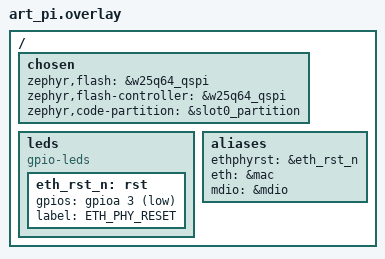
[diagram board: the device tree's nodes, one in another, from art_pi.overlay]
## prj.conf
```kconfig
# # 与 A 相同的网络 / zperf / shell 基础：
# CONFIG_NETWORKING=y
# CONFIG_NET_L2_ETHERNET=y
# CONFIG_NET_IPV4=y

# CONFIG_NET_SOCKETS=y
# CONFIG_NET_UDP=y            # 你已开；确认仍为 y
# CONFIG_NET_TCP=y            # 继续保持关闭，省 ROM

# CONFIG_NET_DHCPV4=y
# CONFIG_NET_IPV6=y
# CONFIG_DNS_RESOLVER=y

# CONFIG_NET_ZPERF=y
# CONFIG_ZPERF_SESSION_PER_THREAD=n            # 关多会话节省体积 :contentReference[oaicite:6]{index=6}

# CONFIG_NET_SHELL=y                           # 只要 ping / iface 等基础命令即可 :contentReference[oaicite:7]{index=7}

# CONFIG_SHELL=y
# CONFIG_SHELL_BACKEND_SERIAL=y
# CONFIG_SHELL_MINIMAL=y                       # 极简 Shell :contentReference[oaicite:8]{index=8}
# CONFIG_SHELL_CMDS=y
# CONFIG_SHELL_TAB=y
# CONFIG_SHELL_TAB_AUTOCOMPLETION=y           # 需要自动补全就开；非常在意体积可关 :contentReference[oaicite:9]{index=9}
# CONFIG_SHELL_HELP=y
# CONFIG_SHELL_HISTORY=y

# # 完全关闭日志（最省 Flash；失去时间戳）
# CONFIG_LOG=n

# CONFIG_ETH_STM32_HAL=y

# # 只扩 TX，不动 RX（下载方向现在速度已经很高）  增加作用不大
# # CONFIG_NET_PKT_TX_COUNT=48
# # CONFIG_NET_BUF_TX_COUNT=192


# # 可选：把单个 net_buf 的数据块扩大，减少一次发送的分片数量
# #（会多占 RAM；若 RAM 够，设 512 是折中；默认通常较小）   此处增加有效果，只能增加一点网速
# CONFIG_NET_BUF_DATA_SIZE=512
# #开启硬件校验和 offload（降低 CPU 负担）
# CONFIG_ETH_STM32_HW_CHECKSUM=y
# #RX 线程保持抢占（接收方向更及时；默认已是 y）
# CONFIG_ETH_STM32_HAL_RX_THREAD_PREEMPTIVE=y



# 与 A 相同的网络 / zperf / shell 基础：
CONFIG_NETWORKING=y
CONFIG_NET_L2_ETHERNET=y
CONFIG_NET_IPV4=y

CONFIG_NET_SOCKETS=y
CONFIG_NET_UDP=y            # 你已开；确认仍为 y
CONFIG_NET_TCP=n            # 继续保持关闭，省 ROM

CONFIG_NET_DHCPV4=y
CONFIG_NET_IPV6=n
CONFIG_DNS_RESOLVER=n

CONFIG_NET_ZPERF=y
CONFIG_ZPERF_SESSION_PER_THREAD=n            # 关多会话节省体积 :contentReference[oaicite:6]{index=6}

CONFIG_NET_SHELL=y                           # 只要 ping / iface 等基础命令即可 :contentReference[oaicite:7]{index=7}

CONFIG_SHELL=y
CONFIG_SHELL_BACKEND_SERIAL=y
CONFIG_SHELL_MINIMAL=y                       # 极简 Shell :contentReference[oaicite:8]{index=8}
CONFIG_SHELL_CMDS=n
CONFIG_SHELL_TAB=n
CONFIG_SHELL_TAB_AUTOCOMPLETION=n            # 需要自动补全就开；非常在意体积可关 :contentReference[oaicite:9]{index=9}
CONFIG_SHELL_HELP=n
CONFIG_SHELL_HISTORY=n

# 完全关闭日志（最省 Flash；失去时间戳）
CONFIG_LOG=n

CONFIG_ETH_STM32_HAL=y

# 只扩 TX，不动 RX（下载方向现在速度已经很高）  增加作用不大
# CONFIG_NET_PKT_TX_COUNT=48
# CONFIG_NET_BUF_TX_COUNT=192


# 可选：把单个 net_buf 的数据块扩大，减少一次发送的分片数量
#（会多占 RAM；若 RAM 够，设 512 是折中；默认通常较小）   此处增加有效果，只能增加一点网速
CONFIG_NET_BUF_DATA_SIZE=512
#开启硬件校验和 offload（降低 CPU 负担）
CONFIG_ETH_STM32_HW_CHECKSUM=y
#RX 线程保持抢占（接收方向更及时；默认已是 y）
#CONFIG_ETH_STM32_HAL_RX_THREAD_PREEMPTIVE=y

CONFIG_PICOLIBC_USE_MODULE=y

#For UDP
CONFIG_NET_ZPERF_MAX_PACKET_SIZE=1470
```

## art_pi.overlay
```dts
/*
 * Copyright (c) 2025 STMicroelectronics
 *
 * SPDX-License-Identifier: Apache-2.0
 */

/*
 * Define the device, controller and partition to be the external memory
 * for running the application in external NOR from MCUboot
 */
/ {
	chosen {
		zephyr,flash = &w25q64_qspi;
		zephyr,flash-controller = &w25q64_qspi;
		zephyr,code-partition = &slot0_partition;
	};
};

/ {
    leds {
        compatible = "gpio-leds";
        status = "okay";

        eth_rst_n: rst {
            gpios = <&gpioa 3 GPIO_ACTIVE_LOW>; 
            label = "ETH_PHY_RESET";
         };
    };

    aliases {
		ethphyrst = &eth_rst_n;   
		eth = &mac;
		mdio = &mdio;
	};
};
```

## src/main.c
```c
/*
 * SPDX-License-Identifier: Apache-2.0
 *
 * STM32 + LAN8720A (RMII) 以太网连网（DHCP）
 * - 使用 Zephyr logging（自带时间戳）
 * - 接口 UP 后立即 net_dhcpv4_restart()（跳过初始随机等待）
 * - 监听链路与 IPv4 地址事件；断线->stop，重连->restart，并在拿到地址时打印
 */

#include <zephyr/kernel.h>
#include <zephyr/device.h>
#include <zephyr/drivers/gpio.h>
#include <zephyr/net/net_if.h>
#include <zephyr/net/net_ip.h>
#include <zephyr/net/net_core.h>
#include <zephyr/net/net_mgmt.h>
#include <zephyr/net/dhcpv4.h>
#include <zephyr/net/ethernet_mgmt.h>
#include <zephyr/logging/log.h>
#include <string.h>
#include <stm32h7xx_hal_eth.h>   // 提供 ETH_TX_DESC_CNT / ETH_RX_DESC_CNT

// LOG_MODULE_REGISTER(app, LOG_LEVEL_INF);

#if !IS_ENABLED(CONFIG_LOG)
  #define LOG_INF(fmt, ...) printk(fmt "\n", ##__VA_ARGS__)
  #define LOG_WRN(fmt, ...) printk("[WRN] " fmt "\n", ##__VA_ARGS__)
  #define LOG_ERR(fmt, ...) printk("[ERR] " fmt "\n", ##__VA_ARGS__)
  #define LOG_MODULE_REGISTER(a, b)
#endif


/* 兼容：若未定义以太网 CARRIER 事件，则退回用 IF_UP/IF_DOWN */
#ifndef NET_EVENT_ETHERNET_CARRIER_ON
#define NET_EVENT_ETHERNET_CARRIER_ON  NET_EVENT_IF_UP
#endif
#ifndef NET_EVENT_ETHERNET_CARRIER_OFF
#define NET_EVENT_ETHERNET_CARRIER_OFF NET_EVENT_IF_DOWN
#endif

#define ETH_ALIAS_NODE DT_ALIAS(eth)        /* &mac */
#define ETH_RST_ALIAS  DT_ALIAS(ethphyrst)  /* 复位脚别名（可选） */

#if !DT_NODE_HAS_STATUS(ETH_ALIAS_NODE, okay)
#error "eth alias not found/disabled"
#endif

#if DT_NODE_HAS_STATUS(ETH_RST_ALIAS, okay)
static const struct gpio_dt_spec phy_rst = GPIO_DT_SPEC_GET(ETH_RST_ALIAS, gpios);
#endif

static struct net_mgmt_event_callback cb_link;
static struct net_mgmt_event_callback cb_ipv4;

static void print_ipv4_info(struct net_if *iface)
{
	char buf[NET_IPV4_ADDR_LEN];

	const struct in_addr *addr =
		net_if_ipv4_get_global_addr(iface, NET_ADDR_PREFERRED);
	if (!addr) {
		LOG_INF("IPv4 not configured");
		return;
	}

	struct in_addr mask = net_if_ipv4_get_netmask_by_addr(iface, addr);
	struct in_addr gw   = net_if_ipv4_get_gw(iface);

	LOG_INF("IPv4 addr: %s",  net_addr_ntop(AF_INET, addr,  buf, sizeof buf));
	LOG_INF("IPv4 mask: %s",  net_addr_ntop(AF_INET, &mask, buf, sizeof buf));
	LOG_INF("IPv4  gw : %s",  net_addr_ntop(AF_INET, &gw,   buf, sizeof buf));
}

static void print_mac(struct net_if *iface)
{
	const struct net_linkaddr *ll = net_if_get_link_addr(iface);
	LOG_INF("IF MAC: %02X:%02X:%02X:%02X:%02X:%02X",
		ll->addr[0], ll->addr[1], ll->addr[2],
		ll->addr[3], ll->addr[4], ll->addr[5]);
}

/* 可选：PHY 复位（低有效示例） */
static void phy_reset_pulse(void)
{
#if DT_NODE_HAS_STATUS(ETH_RST_ALIAS, okay)
	if (!device_is_ready(phy_rst.port)) {
		LOG_WRN("PHY reset GPIO not ready");
		return;
	}
	gpio_pin_configure_dt(&phy_rst, GPIO_OUTPUT_ACTIVE); /* ACTIVE=有效电平（若 ACTIVE_LOW 即拉低） */
	k_msleep(50);                                        /* 复位保持 ≥50ms 更稳 */
	gpio_pin_set_dt(&phy_rst, 0);                        /* 释放复位 */
	k_msleep(100);                                       /* 等 REF_CLK/自协商启动 */
#endif
}

/* 链路事件：掉线->stop；上线->restart（快速获取） */
static void link_event_handler(struct net_mgmt_event_callback *cb,
                               uint64_t mgmt_event, struct net_if *iface)
{
	if (mgmt_event == NET_EVENT_ETHERNET_CARRIER_OFF) {
#if IS_ENABLED(CONFIG_NET_DHCPV4)
		(void)net_dhcpv4_stop(iface);
#endif
		LOG_INF("Link DOWN");
	} else if (mgmt_event == NET_EVENT_ETHERNET_CARRIER_ON) {
#if IS_ENABLED(CONFIG_NET_DHCPV4)
		(void)net_dhcpv4_restart(iface);
#endif
		LOG_INF("Link UP -> restart DHCP");
	}
}

/* IPv4 地址事件：新增/更新时打印（断开时提示） */
static void ipv4_event_handler(struct net_mgmt_event_callback *cb,
                               uint64_t mgmt_event, struct net_if *iface)
{
	if (mgmt_event == NET_EVENT_IPV4_ADDR_ADD) {
		LOG_INF("IPv4 acquired");
		print_ipv4_info(iface);
	} else if (mgmt_event == NET_EVENT_IPV4_ADDR_DEL) {
		LOG_INF("IPv4 address removed");
	}
}

void main(void)
{
	LOG_INF("=== STM32 + LAN8720A (RMII) DHCP ===");



	 printk("ETH_TX_DESC_CNT=%d, ETH_RX_DESC_CNT=%d\n",
           (int)ETH_TX_DESC_CNT, (int)ETH_RX_DESC_CNT);

	phy_reset_pulse();

	struct net_if *iface = net_if_get_default();
	if (!iface) {
		LOG_ERR("No default net_if");
		return;
	}

	print_mac(iface);

	/* 注册事件回调（用一个回调掩码同时订阅 ON/OFF；另一个订阅 IPv4 地址增删） */
	net_mgmt_init_event_callback(&cb_link, link_event_handler,
		NET_EVENT_ETHERNET_CARRIER_ON | NET_EVENT_ETHERNET_CARRIER_OFF |
		NET_EVENT_IF_UP | NET_EVENT_IF_DOWN);
	net_mgmt_add_event_callback(&cb_link);

	net_mgmt_init_event_callback(&cb_ipv4, ipv4_event_handler,
		NET_EVENT_IPV4_ADDR_ADD | NET_EVENT_IPV4_ADDR_DEL);
	net_mgmt_add_event_callback(&cb_ipv4);

	/* 接口 UP 后直接 restart DHCP（跳过首次随机等待） */
	net_if_up(iface);
#if IS_ENABLED(CONFIG_NET_DHCPV4)
	(void)net_dhcpv4_restart(iface);
#endif

	/* 主循环保持存活；事件回调会在每次重连时重新打印 IP */
	while (1) {
		k_sleep(K_SECONDS(5));
	}
}
```

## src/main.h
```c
// #pragma once

/* 先包含 HAL ETH 头，再覆盖它里面的默认宏（通常=4/1524） */
// #include <stm32h7xx_hal_eth.h>
// #include <stm32h7xx_hal_conf.h>

/* 安全起见先 undef，避免重定义告警 */
// #ifdef ETH_TX_DESC_CNT
// #undef ETH_TX_DESC_CNT
// #endif
// #ifdef ETH_RX_DESC_CNT
// #undef ETH_RX_DESC_CNT
// #endif
// #ifdef ETH_TX_BUF_SIZE
// #undef ETH_TX_BUF_SIZE
// #endif
// #ifdef ETH_RX_BUF_SIZE
// #undef ETH_RX_BUF_SIZE
// #endif

// /* 你的目标配置（只增 RAM，不涨 ROM） */
// #define ETH_TX_DESC_CNT 16
// #define ETH_RX_DESC_CNT 16
// #define ETH_TX_BUF_SIZE 1536
// #define ETH_RX_BUF_SIZE 1536
```
